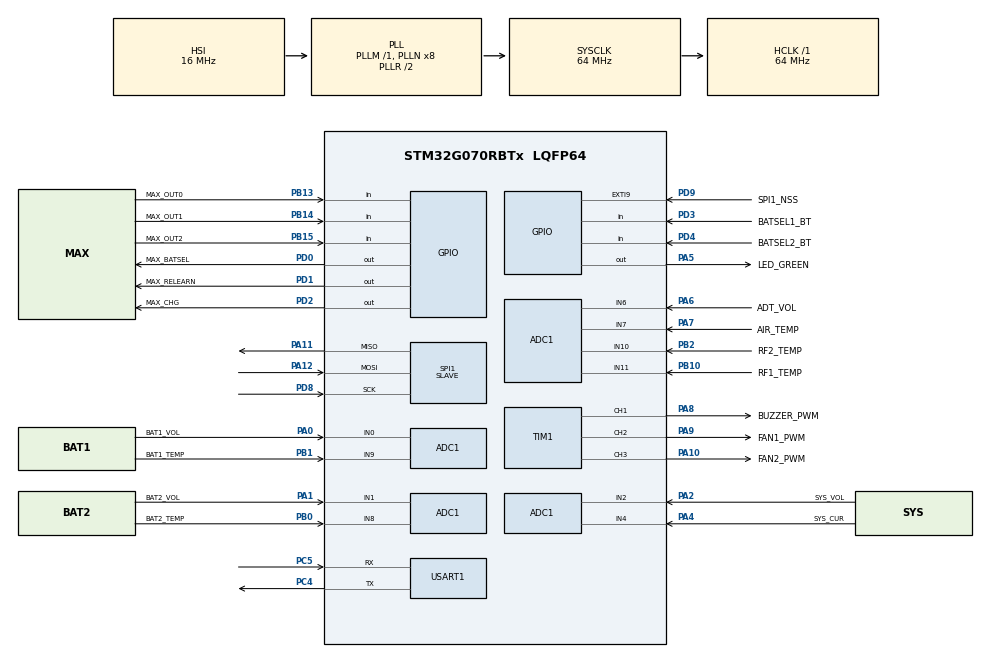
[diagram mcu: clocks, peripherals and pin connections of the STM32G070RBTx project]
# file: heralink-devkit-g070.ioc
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ADC1.Channel-3\#ChannelRegularConversion=ADC_CHANNEL_0
ADC1.Channel-4\#ChannelRegularConversion=ADC_CHANNEL_1
ADC1.Channel-5\#ChannelRegularConversion=ADC_CHANNEL_2
ADC1.Channel-6\#ChannelRegularConversion=ADC_CHANNEL_6
ADC1.Channel-7\#ChannelRegularConversion=ADC_CHANNEL_VREFINT
ADC1.ContinuousConvMode=ENABLE
ADC1.DMAContinuousRequests=ENABLE
ADC1.NbrOfConversion=5
ADC1.NbrOfConversionFlag=1
ADC1.OversamplingMode=ENABLE
ADC1.Rank-3\#ChannelRegularConversion=1
ADC1.Rank-4\#ChannelRegularConversion=2
ADC1.Rank-5\#ChannelRegularConversion=3
ADC1.Rank-6\#ChannelRegularConversion=4
ADC1.Rank-7\#ChannelRegularConversion=5
ADC1.Ratio=ADC_OVERSAMPLING_RATIO_16
ADC1.RightBitShift=ADC_RIGHTBITSHIFT_4
ADC1.SamplingTime-3\#ChannelRegularConversion=ADC_SAMPLINGTIME_COMMON_1
ADC1.SamplingTime-4\#ChannelRegularConversion=ADC_SAMPLINGTIME_COMMON_1
ADC1.SamplingTime-5\#ChannelRegularConversion=ADC_SAMPLINGTIME_COMMON_1
ADC1.SamplingTime-6\#ChannelRegularConversion=ADC_SAMPLINGTIME_COMMON_1
ADC1.SamplingTime-7\#ChannelRegularConversion=ADC_SAMPLINGTIME_COMMON_1
ADC1.SamplingTimeCommon1=ADC_SAMPLETIME_39CYCLES_5
ADC1.SelectedChannel=ADC_CHANNEL_0|ADC_CHANNEL_1|ADC_CHANNEL_2|ADC_CHANNEL_4|ADC_CHANNEL_6|ADC_CHANNEL_7|ADC_CHANNEL_VREFINT|ADC_CHANNEL_8|ADC_CHANNEL_9|ADC_CHANNEL_10|ADC_CHANNEL_11
ADC1.master=1
Dma.ADC1.0.Direction=DMA_PERIPH_TO_MEMORY
Dma.ADC1.0.EventEnable=DISABLE
Dma.ADC1.0.Instance=DMA1_Channel1
Dma.ADC1.0.MemDataAlignment=DMA_MDATAALIGN_HALFWORD
Dma.ADC1.0.MemInc=DMA_MINC_ENABLE
Dma.ADC1.0.Mode=DMA_CIRCULAR
Dma.ADC1.0.PeriphDataAlignment=DMA_PDATAALIGN_HALFWORD
Dma.ADC1.0.PeriphInc=DMA_PINC_DISABLE
Dma.ADC1.0.Polarity=HAL_DMAMUX_REQ_GEN_RISING
Dma.ADC1.0.Priority=DMA_PRIORITY_LOW
Dma.ADC1.0.RequestNumber=1
Dma.ADC1.0.SignalID=NONE
Dma.ADC1.0.SyncEnable=DISABLE
Dma.ADC1.0.SyncPolarity=HAL_DMAMUX_SYNC_NO_EVENT
Dma.ADC1.0.SyncRequestNumber=1
Dma.ADC1.0.SyncSignalID=NONE
Dma.Request0=ADC1
Dma.Request1=SPI1_RX
Dma.Request2=SPI1_TX
Dma.SPI1_RX.1.Direction=DMA_PERIPH_TO_MEMORY
Dma.SPI1_RX.1.EventEnable=DISABLE
Dma.SPI1_RX.1.Instance=DMA1_Channel2
Dma.SPI1_RX.1.MemDataAlignment=DMA_MDATAALIGN_BYTE
Dma.SPI1_RX.1.MemInc=DMA_MINC_ENABLE
Dma.SPI1_RX.1.Mode=DMA_NORMAL
Dma.SPI1_RX.1.PeriphDataAlignment=DMA_PDATAALIGN_BYTE
Dma.SPI1_RX.1.PeriphInc=DMA_PINC_DISABLE
Dma.SPI1_RX.1.Polarity=HAL_DMAMUX_REQ_GEN_RISING
Dma.SPI1_RX.1.Priority=DMA_PRIORITY_MEDIUM
Dma.SPI1_RX.1.RequestNumber=1
Dma.SPI1_RX.1.SignalID=NONE
Dma.SPI1_RX.1.SyncEnable=DISABLE
Dma.SPI1_RX.1.SyncPolarity=HAL_DMAMUX_SYNC_NO_EVENT
Dma.SPI1_RX.1.SyncRequestNumber=1
Dma.SPI1_RX.1.SyncSignalID=NONE
Dma.SPI1_TX.2.Direction=DMA_MEMORY_TO_PERIPH
Dma.SPI1_TX.2.EventEnable=DISABLE
Dma.SPI1_TX.2.Instance=DMA1_Channel3
Dma.SPI1_TX.2.MemDataAlignment=DMA_MDATAALIGN_BYTE
Dma.SPI1_TX.2.MemInc=DMA_MINC_ENABLE
Dma.SPI1_TX.2.Mode=DMA_NORMAL
Dma.SPI1_TX.2.PeriphDataAlignment=DMA_PDATAALIGN_BYTE
Dma.SPI1_TX.2.PeriphInc=DMA_PINC_DISABLE
Dma.SPI1_TX.2.Polarity=HAL_DMAMUX_REQ_GEN_RISING
Dma.SPI1_TX.2.Priority=DMA_PRIORITY_MEDIUM
Dma.SPI1_TX.2.RequestNumber=1
Dma.SPI1_TX.2.SignalID=NONE
Dma.SPI1_TX.2.SyncEnable=DISABLE
Dma.SPI1_TX.2.SyncPolarity=HAL_DMAMUX_SYNC_NO_EVENT
Dma.SPI1_TX.2.SyncRequestNumber=1
Dma.SPI1_TX.2.SyncSignalID=NONE
FREERTOS.Tasks01=defaultTask,24,128,StartDefaultTask,Default,NULL,Dynamic,NULL,NULL
FREERTOS.configTOTAL_HEAP_SIZE=10*1024
FREERTOS.configUSE_NEWLIB_REENTRANT=1
Mcu.Family=STM32G0
Mcu.Name=STM32G070RBTx
Mcu.Package=LQFP64
NVIC.DMA1_Channel1_IRQn=true\:3\:0\:false\:false\:true\:false\:false\:true\:true
NVIC.DMA1_Channel2_3_IRQn=true\:3\:0\:false\:false\:true\:false\:false\:true\:true
NVIC.EXTI4_15_IRQn=true\:1\:0\:true\:false\:true\:false\:true\:true\:true
NVIC.TIM3_IRQn=true\:3\:0\:false\:false\:true\:false\:false\:true\:true
NVIC.TimeBase=TIM3_IRQn
NVIC.TimeBaseIP=TIM3
PA0.GPIO_Label=BAT1_VOL
PA0.Mode=IN0
PA0.Signal=ADC1_IN0
PA1.GPIO_Label=BAT2_VOL
PA1.Mode=IN1
PA1.Signal=ADC1_IN1
PA10.GPIO_Label=FAN2_PWM
PA10.Signal=S_TIM1_CH3
PA11\ [PA9].GPIO_PuPd=GPIO_PULLUP
PA11\ [PA9].GPIO_Speed=GPIO_SPEED_FREQ_VERY_HIGH
PA11\ [PA9].Mode=Full_Duplex_Slave
PA11\ [PA9].Signal=SPI1_MISO
PA12\ [PA10].GPIO_PuPd=GPIO_PULLUP
PA12\ [PA10].GPIO_Speed=GPIO_SPEED_FREQ_VERY_HIGH
PA12\ [PA10].Mode=Full_Duplex_Slave
PA12\ [PA10].Signal=SPI1_MOSI
PA13.GPIO_Label=TMS
PA13.Mode=Serial_Wire
PA13.Signal=SYS_SWDIO
PA14-BOOT0.GPIO_Label=TCK
PA14-BOOT0.Mode=Serial_Wire
PA14-BOOT0.Signal=SYS_SWCLK
PA2.GPIO_Label=SYS_VOL
PA2.Mode=IN2
PA2.Signal=ADC1_IN2
PA4.GPIO_Label=SYS_CUR
PA4.Mode=IN4
PA4.Signal=ADC1_IN4
PA5.GPIO_Label=LED_GREEN
PA5.GPIO_Speed=GPIO_SPEED_FREQ_HIGH
PA5.Signal=GPIO_Output
PA6.GPIO_Label=ADT_VOL
PA6.Mode=IN6
PA6.Signal=ADC1_IN6
PA7.GPIO_Label=AIR_TEMP
PA7.Mode=IN7
PA7.Signal=ADC1_IN7
PA8.GPIO_Label=BUZZER_PWM
PA8.Signal=S_TIM1_CH1
PA9.GPIO_Label=FAN1_PWM
PA9.Signal=S_TIM1_CH2
PB0.GPIO_Label=BAT2_TEMP
PB0.Mode=IN8
PB0.Signal=ADC1_IN8
PB1.GPIO_Label=BAT1_TEMP
PB1.Mode=IN9
PB1.Signal=ADC1_IN9
PB10.GPIO_Label=RF1_TEMP
PB10.Mode=IN11
PB10.Signal=ADC1_IN11
PB13.GPIO_Label=MAX_OUT0
PB13.GPIO_PuPd=GPIO_PULLDOWN
PB13.Signal=GPIO_Input
PB14.GPIO_Label=MAX_OUT1
PB14.GPIO_PuPd=GPIO_PULLDOWN
PB14.Signal=GPIO_Input
PB15.GPIO_Label=MAX_OUT2
PB15.GPIO_PuPd=GPIO_PULLDOWN
PB15.Signal=GPIO_Input
PB2.GPIO_Label=RF2_TEMP
PB2.Mode=IN10
PB2.Signal=ADC1_IN10
PC13.Mode=SYS_WakeUp1
PC13.Signal=SYS_WKUP2
PC14-OSC32_IN\ (PC14).Mode=LSE-External-Oscillator
PC14-OSC32_IN\ (PC14).Signal=RCC_OSC32_IN
PC15-OSC32_OUT\ (PC15).Mode=LSE-External-Oscillator
PC15-OSC32_OUT\ (PC15).Signal=RCC_OSC32_OUT
PC4.Mode=Asynchronous
PC4.Signal=USART1_TX
PC5.Mode=Asynchronous
PC5.Signal=USART1_RX
PD0.GPIO_Label=MAX_BATSEL
PD0.GPIO_PuPd=GPIO_PULLDOWN
PD0.Signal=GPIO_Output
PD1.GPIO_Label=MAX_RELEARN
PD1.GPIO_PuPd=GPIO_PULLDOWN
PD1.Signal=GPIO_Output
PD2.GPIO_Label=MAX_CHG
PD2.GPIO_PuPd=GPIO_PULLDOWN
PD2.Signal=GPIO_Output
PD3.GPIO_Label=BATSEL1_BT
PD3.GPIO_PuPd=GPIO_PULLDOWN
PD3.Signal=GPIO_Input
PD4.GPIO_Label=BATSEL2_BT
PD4.GPIO_PuPd=GPIO_PULLDOWN
PD4.Signal=GPIO_Input
PD8.GPIO_PuPd=GPIO_PULLUP
PD8.GPIO_Speed=GPIO_SPEED_FREQ_VERY_HIGH
PD8.Mode=Full_Duplex_Slave
PD8.Signal=SPI1_SCK
PD9.GPIO_Label=SPI1_NSS
PD9.GPIO_ModeDefaultEXTI=GPIO_MODE_IT_RISING_FALLING
PD9.GPIO_PuPd=GPIO_PULLUP
PD9.Signal=GPXTI9
PF0-OSC_IN\ (PF0).GPIO_Label=MCO
PF0-OSC_IN\ (PF0).Mode=HSE-External-Clock-Source
PF0-OSC_IN\ (PF0).Signal=RCC_OSC_IN
ProjectManager.HeapSize=0x200
ProjectManager.StackSize=0x400
ProjectManager.TargetToolchain=STM32CubeIDE
RCC.ADCFreq_Value=64000000
RCC.AHBFreq_Value=64000000
RCC.APB1CLKDivider=RCC_HCLK_DIV2
RCC.CortexFreq_Value=64000000
RCC.EXTERNAL_CLOCK_VALUE=12288000
RCC.HCLKFreq_Value=64000000
RCC.HSE_VALUE=8000000
RCC.HSI_VALUE=16000000
RCC.SYSCLKFreq_VALUE=64000000
RCC.SYSCLKSource=RCC_SYSCLKSOURCE_PLLCLK
RCC.VCOOutputFreq_Value=128000000
SH.S_TIM1_CH1.0=TIM1_CH1,PWM Generation1 CH1
SH.S_TIM1_CH2.0=TIM1_CH2,PWM Generation2 CH2
SH.S_TIM1_CH3.0=TIM1_CH3,PWM Generation3 CH3
SPI1.CRCCalculation=SPI_CRCCALCULATION_DISABLE
SPI1.DataSize=SPI_DATASIZE_8BIT
SPI1.Direction=SPI_DIRECTION_2LINES
SPI1.Mode=SPI_MODE_SLAVE
SPI1.VirtualType=VM_SLAVE
TIM1.Channel-PWM\ Generation1\ CH1=TIM_CHANNEL_1
TIM1.Channel-PWM\ Generation2\ CH2=TIM_CHANNEL_2
TIM1.Channel-PWM\ Generation3\ CH3=TIM_CHANNEL_3
USART1.VirtualMode-Asynchronous=VM_ASYNC
VP_ADC1_Vref_Input.Mode=IN-Vrefint
VP_FREERTOS_VS_CMSIS_V2.Mode=CMSIS_V2
VP_SYS_VS_tim3.Mode=TIM3
VP_TIM1_VS_ClockSourceINT.Mode=Internal
board=NUCLEO-G070RB

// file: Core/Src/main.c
/* USER CODE BEGIN Header */
/**
  ******************************************************************************
  * @file           : main.c
  * @brief          : Main program body
  ******************************************************************************
  * @attention
  *
  * Copyright (c) 2023 STMicroelectronics.
  * All rights reserved.
  *
  * This software is licensed under terms that can be found in the LICENSE file
  * in the root directory of this software component.
  * If no LICENSE file comes with this software, it is provided AS-IS.
  *
  ******************************************************************************
  */
/* USER CODE END Header */
#include "main.h"
#include "cmsis_os.h"
#include "adc.h"
#include "dma.h"
#include "spi.h"
#include "tim.h"
#include "usart.h"
#include "gpio.h"

/* USER CODE BEGIN Includes */
#include "heralink.h"
/* USER CODE END Includes */

void SystemClock_Config(void);
void MX_FREERTOS_Init(void);

int main(void)
{

  /* MCU Configuration--------------------------------------------------------*/

  /* Reset of all peripherals, Initializes the Flash interface and the Systick. */
  HAL_Init();

  /* Configure the system clock */
  SystemClock_Config();

  /* Initialize all configured peripherals */
  MX_GPIO_Init();
  MX_DMA_Init();
  MX_USART1_UART_Init();
  MX_ADC1_Init();
  MX_SPI1_Init();
  MX_TIM1_Init();
  /* USER CODE BEGIN 2 */

  heralink_main_init();

  /* USER CODE END 2 */

  /* Init scheduler */
  osKernelInitialize();  /* Call init function for freertos objects (in freertos.c) */
  MX_FREERTOS_Init();

  /* Start scheduler */
  osKernelStart();

  /* We should never get here as control is now taken by the scheduler */
  /* Infinite loop */
  while (1)
  {

  }
}

void SystemClock_Config(void)
{
  RCC_OscInitTypeDef RCC_OscInitStruct = {0};
  RCC_ClkInitTypeDef RCC_ClkInitStruct = {0};

  /** Configure the main internal regulator output voltage
  */
  HAL_PWREx_ControlVoltageScaling(PWR_REGULATOR_VOLTAGE_SCALE1);

  /** Initializes the RCC Oscillators according to the specified parameters
  * in the RCC_OscInitTypeDef structure.
  */
  RCC_OscInitStruct.OscillatorType = RCC_OSCILLATORTYPE_HSI;
  RCC_OscInitStruct.HSIState = RCC_HSI_ON;
  RCC_OscInitStruct.HSIDiv = RCC_HSI_DIV1;
  RCC_OscInitStruct.HSICalibrationValue = RCC_HSICALIBRATION_DEFAULT;
  RCC_OscInitStruct.PLL.PLLState = RCC_PLL_ON;
  RCC_OscInitStruct.PLL.PLLSource = RCC_PLLSOURCE_HSI;
  RCC_OscInitStruct.PLL.PLLM = RCC_PLLM_DIV1;
  RCC_OscInitStruct.PLL.PLLN = 8;
  RCC_OscInitStruct.PLL.PLLP = RCC_PLLP_DIV2;
  RCC_OscInitStruct.PLL.PLLR = RCC_PLLR_DIV2;
  if (HAL_RCC_OscConfig(&RCC_OscInitStruct) != HAL_OK)
  {
    Error_Handler();
  }

  /** Initializes the CPU, AHB and APB buses clocks
  */
  RCC_ClkInitStruct.ClockType = RCC_CLOCKTYPE_HCLK|RCC_CLOCKTYPE_SYSCLK
                              |RCC_CLOCKTYPE_PCLK1;
  RCC_ClkInitStruct.SYSCLKSource = RCC_SYSCLKSOURCE_PLLCLK;
  RCC_ClkInitStruct.AHBCLKDivider = RCC_SYSCLK_DIV1;
  RCC_ClkInitStruct.APB1CLKDivider = RCC_HCLK_DIV2;

  if (HAL_RCC_ClockConfig(&RCC_ClkInitStruct, FLASH_LATENCY_2) != HAL_OK)
  {
    Error_Handler();
  }
}

void HAL_TIM_PeriodElapsedCallback(TIM_HandleTypeDef *htim)
{
  if (htim->Instance == TIM3) {
    HAL_IncTick();
  }
}

void Error_Handler(void)
{
  __disable_irq();
  while (1)
  {
  }
}

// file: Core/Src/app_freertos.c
/* USER CODE BEGIN Header */
/**
  ******************************************************************************
  * File Name          : app_freertos.c
  * Description        : Code for freertos applications
  ******************************************************************************
  * @attention
  *
  * Copyright (c) 2023 STMicroelectronics.
  * All rights reserved.
  *
  * This software is licensed under terms that can be found in the LICENSE file
  * in the root directory of this software component.
  * If no LICENSE file comes with this software, it is provided AS-IS.
  *
  ******************************************************************************
  */
/* USER CODE END Header */

#include "FreeRTOS.h"
#include "task.h"
#include "main.h"
#include "cmsis_os.h"

/* USER CODE BEGIN Includes */
#include "adc.h"
#include "usart.h"
/* USER CODE END Includes */

/* USER CODE BEGIN Variables */

uint32_t ADC_FUCK;
int counter_testing;
uint16_t val;
uint8_t buffer[20];
//uint16_t *pointer = (uint16_t*)0x1FFF7A2A;

/* USER CODE END Variables */
/* Definitions for defaultTask */
osThreadId_t defaultTaskHandle;
const osThreadAttr_t defaultTask_attributes = {
  .name = "defaultTask",
  .priority = (osPriority_t) osPriorityNormal,
  .stack_size = 128 * 4
};

void StartDefaultTask(void *argument);

void MX_FREERTOS_Init(void); /* (MISRA C 2004 rule 8.1) */

void MX_FREERTOS_Init(void) {

  /* Create the thread(s) */
  /* creation of defaultTask */
  defaultTaskHandle = osThreadNew(StartDefaultTask, NULL, &defaultTask_attributes);

}

void StartDefaultTask(void *argument)
{
  /* USER CODE BEGIN StartDefaultTask */
//		  val = *pointer;
//	val = *(uint16_t*)VREF_INT;

//		  ADC_FUCK = HAL_ADCEx_Calibration_GetValue(&hadc1);
//		  HAL_ADCEx_Calibration_SetValue(&hadc1, ADC_FUCK);
  /* Infinite loop */
  for(;;)
  {
	  osDelay(1);
//	  counter_testing++;
//	  sprintf(buffer, "WTF: %d", VREFINT_CAL);

  }
  /* USER CODE END StartDefaultTask */
}
